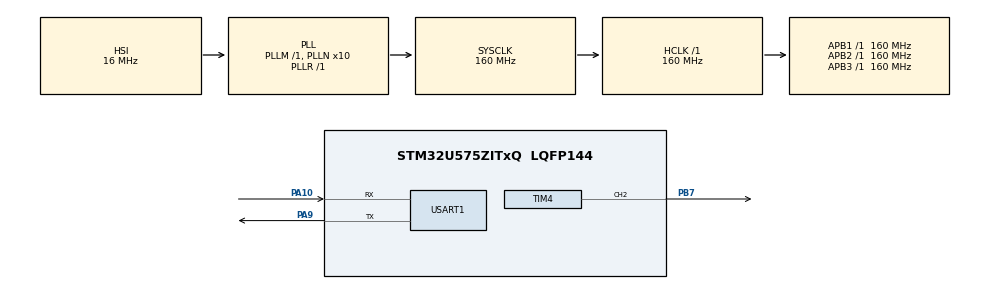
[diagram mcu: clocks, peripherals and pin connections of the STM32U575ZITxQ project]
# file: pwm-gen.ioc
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CORTEX_M33_NS.userName=CORTEX_M33
Mcu.Family=STM32U5
Mcu.Name=STM32U575ZITxQ
Mcu.Package=LQFP144
NVIC.PriorityGroup=NVIC_PRIORITYGROUP_3
PA10.Mode=Asynchronous
PA10.Signal=USART1_RX
PA13\ (JTMS/SWDIO).Mode=Trace_Asynchronous_SW
PA13\ (JTMS/SWDIO).Signal=DEBUG_JTMS-SWDIO
PA14\ (JTCK/SWCLK).Mode=Trace_Asynchronous_SW
PA14\ (JTCK/SWCLK).Signal=DEBUG_JTCK-SWCLK
PA9.Mode=Asynchronous
PA9.Signal=USART1_TX
PB3\ (JTDO/TRACESWO).Mode=Trace_Asynchronous_SW
PB3\ (JTDO/TRACESWO).Signal=DEBUG_JTDO-SWO
PB7.Signal=S_TIM4_CH2
PWR.PowerMode=PWR_SMPS_SUPPLY
ProjectManager.HeapSize=0x200
ProjectManager.StackSize=0x400
ProjectManager.TargetToolchain=STM32CubeIDE
RCC.ADCFreq_Value=16000000
RCC.AHBFreq_Value=160000000
RCC.APB1Freq_Value=160000000
RCC.APB1TimFreq_Value=160000000
RCC.APB2Freq_Value=160000000
RCC.APB2TimFreq_Value=160000000
RCC.APB3Freq_Value=160000000
RCC.CortexFreq_Value=160000000
RCC.DACCLockSelectionVirtual=RCC_DAC1CLKSOURCE_LSI
RCC.EPOD_VALUE=16000000
RCC.HCLKFreq_Value=160000000
RCC.HSE_VALUE=16000000
RCC.HSI48_VALUE=48000000
RCC.HSI_VALUE=16000000
RCC.LSE_VALUE=32768
RCC.LSIDIV_VALUE=32000
RCC.MSIClockRange=RCC_MSIRANGE_0
RCC.MSI_VALUE=48000000
RCC.PLL1R=1
RCC.PLL2FRACN=0
RCC.PLL3FRACN=0
RCC.PLLFRACN=0
RCC.PLLN=10
RCC.PLLSourceVirtual=RCC_PLLSOURCE_HSI
RCC.SYSCLKFreq_VALUE=160000000
RCC.SYSCLKSource=RCC_SYSCLKSOURCE_PLLCLK
RCC.USBFreq_Value=48000000
RCC.VCOOutputFreq_Value=160000000
SH.S_TIM4_CH2.0=TIM4_CH2,PWM Generation2 CH2
TIM4.AutoReloadPreload=TIM_AUTORELOAD_PRELOAD_DISABLE
TIM4.Channel-PWM\ Generation2\ CH2=TIM_CHANNEL_2
TIM4.OCFastMode_PWM-PWM\ Generation2\ CH2=TIM_OCFAST_ENABLE
TIM4.PeriodNoDither=1000
TIM4.Prescaler=0
USART1.VirtualMode-Asynchronous=VM_ASYNC
VP_ICACHE_VS_ENABLE_ICACHE_MEMORY.Mode=Memoryregions
VP_ICACHE_VS_ICACHE.Mode=DefaultMode
VP_LPBAMQUEUE_VS_QUEUE.Mode=QUEUEMODE
VP_LPBAM_VS_SIG1.Mode=SmartRun
VP_LPBAM_VS_SIG4.Mode=LPDMA1
VP_MEMORYMAP_VS_MEMORYMAP.Mode=CurAppReg
VP_PWR_VS_DBSignals.Mode=DisableDeadBatterySignals
VP_PWR_VS_LPOM.Mode=PowerOptimisation
VP_PWR_VS_SECSignals.Mode=Security/Privilege
VP_TIM4_VS_ClockSourceINT.Mode=Internal
board=NUCLEO-U575ZI-Q

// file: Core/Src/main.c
/* USER CODE BEGIN Header */
/**
 ******************************************************************************
 * @file           : main.c
 * @brief          : Main program body
 ******************************************************************************
 * @attention
 *
 * Copyright (c) 2024 STMicroelectronics.
 * All rights reserved.
 *
 * This software is licensed under terms that can be found in the LICENSE file
 * in the root directory of this software component.
 * If no LICENSE file comes with this software, it is provided AS-IS.
 *
 ******************************************************************************
 */
/* USER CODE END Header */
#include "main.h"

/* USER CODE BEGIN Includes */
#include <stdio.h>
/* USER CODE END Includes */

TIM_HandleTypeDef htim4;

UART_HandleTypeDef huart1;

/* USER CODE BEGIN PV */
uint32_t begin;
uint32_t end;
uint32_t diff;
/* USER CODE END PV */

void SystemClock_Config(void);
static void SystemPower_Config(void);
static void MX_GPIO_Init(void);
static void MX_ICACHE_Init(void);
static void MX_TIM4_Init(void);
static void MX_USART1_UART_Init(void);

/* USER CODE BEGIN 0 */
int _write(int le, char *ptr, int len) {
	int DataIdx;

	for (DataIdx = 0; DataIdx < len; DataIdx++) {
		ITM_SendChar(*ptr++);
	}

	return len;
}
/* USER CODE END 0 */

int main(void) {

	/* USER CODE BEGIN 1 */
	begin = DWT->CYCCNT;
	/* USER CODE END 1 */

	/* MCU Configuration--------------------------------------------------------*/

	/* Reset of all peripherals, Initializes the Flash interface and the Systick. */
	HAL_Init();

	/* Configure the system clock */
	SystemClock_Config();

	/* Configure the System Power */
	SystemPower_Config();

	/* Initialize all configured peripherals */
	MX_GPIO_Init();
	MX_ICACHE_Init();
	MX_TIM4_Init();
	MX_USART1_UART_Init();
	/* USER CODE BEGIN 2 */
	HAL_TIM_PWM_Start(&htim4, TIM_CHANNEL_2);

	end = DWT->CYCCNT;
	diff = end - begin;
	printf("%u\n", diff);
	/* USER CODE END 2 */

	/* Infinite loop */
	/* USER CODE BEGIN WHILE */

	while (1) {
		// breathing LED, check clock configuration, because, CubeIDE resolves, then errors at runtime...
		for (int i = 0; i <= 1000; i++) {
			TIM4->CCR2 = i;
			HAL_Delay(1);
		}
		for (int i = 1000; i >= 0; i--) {
			TIM4->CCR2 = i;
			HAL_Delay(1);
		}

		/* USER CODE END WHILE */

	}
}

void SystemClock_Config(void) {
	RCC_OscInitTypeDef RCC_OscInitStruct = { 0 };
	RCC_ClkInitTypeDef RCC_ClkInitStruct = { 0 };

	/** Configure the main internal regulator output voltage
	 */
	if (HAL_PWREx_ControlVoltageScaling(PWR_REGULATOR_VOLTAGE_SCALE1)
			!= HAL_OK) {
		Error_Handler();
	}

	/** Initializes the CPU, AHB and APB buses clocks
	 */
	RCC_OscInitStruct.OscillatorType = RCC_OSCILLATORTYPE_HSI;
	RCC_OscInitStruct.HSIState = RCC_HSI_ON;
	RCC_OscInitStruct.HSICalibrationValue = RCC_HSICALIBRATION_DEFAULT;
	RCC_OscInitStruct.PLL.PLLState = RCC_PLL_ON;
	RCC_OscInitStruct.PLL.PLLSource = RCC_PLLSOURCE_HSI;
	RCC_OscInitStruct.PLL.PLLMBOOST = RCC_PLLMBOOST_DIV1;
	RCC_OscInitStruct.PLL.PLLM = 1;
	RCC_OscInitStruct.PLL.PLLN = 10;
	RCC_OscInitStruct.PLL.PLLP = 2;
	RCC_OscInitStruct.PLL.PLLQ = 2;
	RCC_OscInitStruct.PLL.PLLR = 1;
	RCC_OscInitStruct.PLL.PLLRGE = RCC_PLLVCIRANGE_1;
	RCC_OscInitStruct.PLL.PLLFRACN = 0;
	if (HAL_RCC_OscConfig(&RCC_OscInitStruct) != HAL_OK) {
		Error_Handler();
	}

	/** Initializes the CPU, AHB and APB buses clocks
	 */
	RCC_ClkInitStruct.ClockType = RCC_CLOCKTYPE_HCLK | RCC_CLOCKTYPE_SYSCLK
			| RCC_CLOCKTYPE_PCLK1 | RCC_CLOCKTYPE_PCLK2 | RCC_CLOCKTYPE_PCLK3;
	RCC_ClkInitStruct.SYSCLKSource = RCC_SYSCLKSOURCE_PLLCLK;
	RCC_ClkInitStruct.AHBCLKDivider = RCC_SYSCLK_DIV1;
	RCC_ClkInitStruct.APB1CLKDivider = RCC_HCLK_DIV1;
	RCC_ClkInitStruct.APB2CLKDivider = RCC_HCLK_DIV1;
	RCC_ClkInitStruct.APB3CLKDivider = RCC_HCLK_DIV1;

	if (HAL_RCC_ClockConfig(&RCC_ClkInitStruct, FLASH_LATENCY_4) != HAL_OK) {
		Error_Handler();
	}
}

/**
 * @brief Power Configuration
 * @retval None
 */
static void SystemPower_Config(void) {

	/*
	 * Disable the internal Pull-Up in Dead Battery pins of UCPD peripheral
	 */
	HAL_PWREx_DisableUCPDDeadBattery();

	/*
	 * Switch to SMPS regulator instead of LDO
	 */
	if (HAL_PWREx_ConfigSupply(PWR_SMPS_SUPPLY) != HAL_OK) {
		Error_Handler();
	}
}

static void MX_ICACHE_Init(void) {

	/** Enable instruction cache (default 2-ways set associative cache)
	 */
	if (HAL_ICACHE_Enable() != HAL_OK) {
		Error_Handler();
	}

}

static void MX_TIM4_Init(void) {

	TIM_ClockConfigTypeDef sClockSourceConfig = { 0 };
	TIM_MasterConfigTypeDef sMasterConfig = { 0 };
	TIM_OC_InitTypeDef sConfigOC = { 0 };

	htim4.Instance = TIM4;
	htim4.Init.Prescaler = 0;
	htim4.Init.CounterMode = TIM_COUNTERMODE_UP;
	htim4.Init.Period = 1000;
	htim4.Init.ClockDivision = TIM_CLOCKDIVISION_DIV1;
	htim4.Init.AutoReloadPreload = TIM_AUTORELOAD_PRELOAD_DISABLE;
	if (HAL_TIM_Base_Init(&htim4) != HAL_OK) {
		Error_Handler();
	}
	sClockSourceConfig.ClockSource = TIM_CLOCKSOURCE_INTERNAL;
	if (HAL_TIM_ConfigClockSource(&htim4, &sClockSourceConfig) != HAL_OK) {
		Error_Handler();
	}
	if (HAL_TIM_PWM_Init(&htim4) != HAL_OK) {
		Error_Handler();
	}
	sMasterConfig.MasterOutputTrigger = TIM_TRGO_RESET;
	sMasterConfig.MasterSlaveMode = TIM_MASTERSLAVEMODE_DISABLE;
	if (HAL_TIMEx_MasterConfigSynchronization(&htim4, &sMasterConfig)
			!= HAL_OK) {
		Error_Handler();
	}
	sConfigOC.OCMode = TIM_OCMODE_PWM1;
	sConfigOC.Pulse = 0;
	sConfigOC.OCPolarity = TIM_OCPOLARITY_HIGH;
	sConfigOC.OCFastMode = TIM_OCFAST_ENABLE;
	if (HAL_TIM_PWM_ConfigChannel(&htim4, &sConfigOC, TIM_CHANNEL_2)
			!= HAL_OK) {
		Error_Handler();
	}
	HAL_TIM_MspPostInit(&htim4);

}

static void MX_USART1_UART_Init(void) {

	huart1.Instance = USART1;
	huart1.Init.BaudRate = 115200;
	huart1.Init.WordLength = UART_WORDLENGTH_8B;
	huart1.Init.StopBits = UART_STOPBITS_1;
	huart1.Init.Parity = UART_PARITY_NONE;
	huart1.Init.Mode = UART_MODE_TX_RX;
	huart1.Init.HwFlowCtl = UART_HWCONTROL_NONE;
	huart1.Init.OverSampling = UART_OVERSAMPLING_16;
	huart1.Init.OneBitSampling = UART_ONE_BIT_SAMPLE_DISABLE;
	huart1.Init.ClockPrescaler = UART_PRESCALER_DIV1;
	huart1.AdvancedInit.AdvFeatureInit = UART_ADVFEATURE_NO_INIT;
	if (HAL_UART_Init(&huart1) != HAL_OK) {
		Error_Handler();
	}
	if (HAL_UARTEx_SetTxFifoThreshold(&huart1, UART_TXFIFO_THRESHOLD_1_8)
			!= HAL_OK) {
		Error_Handler();
	}
	if (HAL_UARTEx_SetRxFifoThreshold(&huart1, UART_RXFIFO_THRESHOLD_1_8)
			!= HAL_OK) {
		Error_Handler();
	}
	if (HAL_UARTEx_DisableFifoMode(&huart1) != HAL_OK) {
		Error_Handler();
	}

}

static void MX_GPIO_Init(void) {

	/* GPIO Ports Clock Enable */
	__HAL_RCC_GPIOA_CLK_ENABLE();
	__HAL_RCC_GPIOB_CLK_ENABLE();

}

void Error_Handler(void) {
	__disable_irq();
	while (1) {
	}
}
